# G32R502 register map
Vendor: Geehy Semiconductor Co., Ltd.; Series: G32R5; File version: 1.0
CPU: CM52 r0p1, little endian, MPU, FPU, DSP, VTOR, 4 interrupt priority bits
Registers are 32-bit, read-write, reset 0x0 unless marked. A register's access mark holds for its fields unless they carry their own. Offsets are from the block's base; [hi:lo] are bit positions; {n}, {i} and the like mark numbered series.

## DCCOMP0 — Dual-Clock Comparator
Base 0x40000000
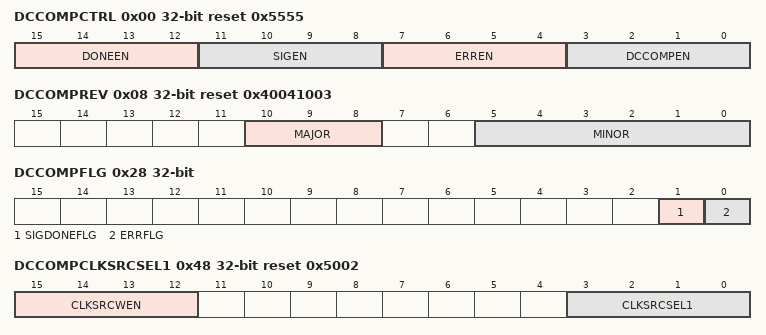
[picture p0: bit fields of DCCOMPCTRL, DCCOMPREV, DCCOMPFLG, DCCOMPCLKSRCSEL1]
0x00 DCCOMPCTRL reset 0x5555 — Global Control Register
  [15:12] DONEEN — DONE Enable
  [11:8] SIGEN — Single Shot Mode Enable
  [7:4] ERREN — Error Enable
  [3:0] DCCOMPEN — DCCOMP Enable
0x08 DCCOMPREV ro reset 0x40041003 — DCCOMP Revision Register
  [10:8] MAJOR — Minor Revision Number
  [5:0] MINOR — Major Revision Number
0x10 DCCOMPCNTSEED0 — Counter 0 Seed Value
  [19:0] CNTSEED0
0x18 DCCOMPVALSEED0 — Valid 0 Seed Value
  [15:0] VALSEED0 — Valid Duration Counter 0 Seed Value
0x20 DCCOMPCNTSEED1 — Counter 1 Seed Value
  [19:0] CNTSEED1
0x28 DCCOMPFLG — DCCOMP Status
  [1] SIGDONEFLG — Single-Shot Done Flag
  [0] ERRFLG — Error Flag
0x30 DCCOMPCLKSRCCNT0 ro — Counter 0 Value
  [19:0] CLKSRCCNT0 — Clock Source 0 counter attached Value
0x38 DCCOMPCLKSRCVAL0 ro — Valid Value 0
  [15:0] CLKSRCVAL0 — Clock Source 0 valid counter attached Value
0x40 DCCOMPCLKSRCCNT1 ro — Counter 1 Value
  [19:0] CLKSRCCNT1 — Clock Source 1 counter attached Value
0x48 DCCOMPCLKSRCSEL1 reset 0x5002 — Clock Source 1
  [15:12] CLKSRCWEN — Counter 1 Clock Source Write Enable
  [3:0] CLKSRCSEL1 — Counter 1 Clock Source Select
0x50 DCCOMPCLKSRCSEL0 reset 0x1 — Clock Source 0
  [3:0] CLKSRCSEL0 — Counter 0 Clock Source Select

## NMI — Non-maskable interrupt
Base 0x400100C0
0x00 NMICFG 16-bit — NMI Configuration Register
  [0] NMIE — Global NMI Enable
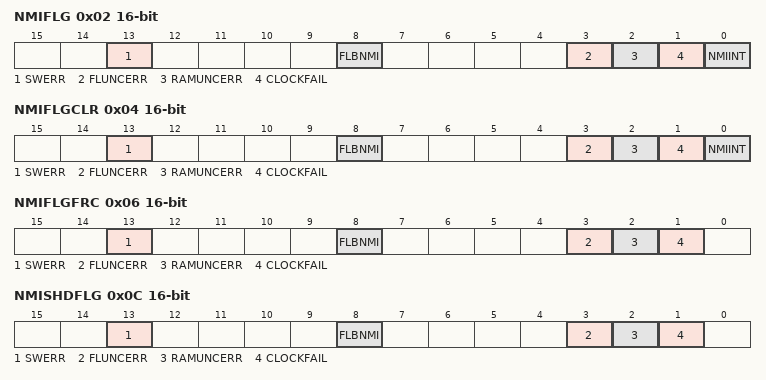
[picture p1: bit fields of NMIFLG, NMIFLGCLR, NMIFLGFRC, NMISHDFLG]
0x02 NMIFLG 16-bit ro — NMI Flag Register (SYSRsn Clear)
  [13] SWERR — Software-Forced NMI Flag
  [8] FLBNMI — FLB NMI Flag
  [3] FLUNCERR — Flash Uncorrectable Error NMI Flag
  [2] RAMUNCERR — RAM Uncorrectable Error NMI Flag
  [1] CLOCKFAIL — Clock Fail NMI Flag
  [0] NMIINT — Global NMI Flag
0x04 NMIFLGCLR 16-bit — NMI Flag Clear Register
  [13] SWERR — Clear the SWERR flag
  [8] FLBNMI — Clear the FLBNMI flag
  [3] FLUNCERR — Clear the FLUNCERR flag
  [2] RAMUNCERR — Clear the RAMUNCERR flag
  [1] CLOCKFAIL — Clear the CLOCKFAIL flag
  [0] NMIINT — Clear the NMIINT flag
0x06 NMIFLGFRC 16-bit — NMI Flag Force Register
  [13] SWERR — Set the SWERR flag
  [8] FLBNMI — Set the FLBNMI flag
  [3] FLUNCERR — Set the FLUNCERR flag
  [2] RAMUNCERR — Set the RAMUNCERR flag
  [1] CLOCKFAIL — Set the CLOCKFAIL flag
0x08 NMIWDCNT 16-bit ro — NMI Watchdog Counter Register
  [15:0] NMIWDCNT — NMI Watchdog Counter
0x0A NMIWDPRD 16-bit reset 0xFFFF — NMI Watchdog Period Register
  [15:0] NMIWDPRD — NMI Watchdog Period
0x0C NMISHDFLG 16-bit ro — NMI Shadow Flag Register
  [13] SWERR — Shadow SWERR flag
  [8] FLBNMI — Shadow FLBNMI flag
  [3] FLUNCERR — Shadow FLUNCERR flag
  [2] RAMUNCERR — Shadow RAMUNCERR flag
  [1] CLOCKFAIL — Shadow CLOCKFAIL flag
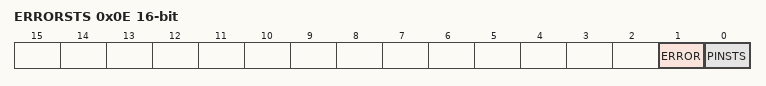
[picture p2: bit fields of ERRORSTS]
0x0E ERRORSTS 16-bit ro — Error Pin Status Register
  [1] ERROR — Error status (sticky)
  [0] PINSTS — Error pin level status
0x10 ERRORSTSCLR 16-bit — Error Pin Status Clear Register
  [0] ERROR — Clear ERRORSTS.ERROR
0x12 ERRORSTSFRC 16-bit — Error Pin Status Force Register
  [0] ERROR — Force ERRORSTS.ERROR
0x14 ERRORSTSCTL 16-bit — Error Pin Status Control Register
  [0] ERRORPOLSEL — Error pin polarity select
0x16 ERRORLOCK 16-bit — Error Pin Control Lock Register
  [0] ERRORCTL — Lock ERRORSTSCTL (write-1-set, clear by reset)

## DBGMCU
Base 0xE0059000
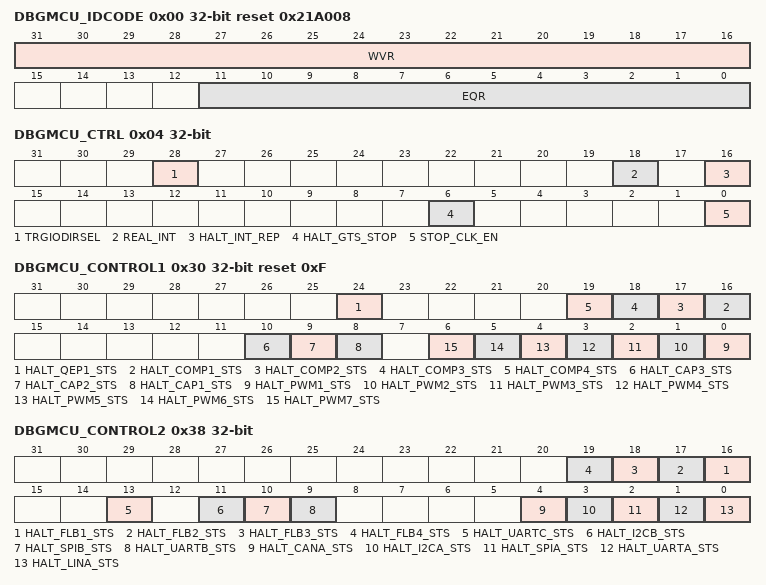
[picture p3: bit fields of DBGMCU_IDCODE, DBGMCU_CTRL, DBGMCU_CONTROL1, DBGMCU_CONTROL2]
0x00 DBGMCU_IDCODE reset 0x21A008 — Device ID register
  [31:16] WVR — Wafer Version Recognition
  [11:0] EQR — Equipment Recognition
0x04 DBGMCU_CTRL — Debug MCU Control register
  [28] TRGIODIRSEL — TRGIO direction select
  [18] REAL_INT — Interrupt run cannot enter HALT when CPU in real-time mode
  [16] HALT_INT_REP — The response is interrupt when CPU in HALT mode
  [6] HALT_GTS_STOP — The global timestamp is stop when CPU enters HALT mode
  [0] STOP_CLK_EN — Enable the system clock when MCU is debugged in stop mode
0x30 DBGMCU_CONTROL1 reset 0xF — CPU Debug MCU configuration register 1
  [24] HALT_QEP1_STS — Configure QEP1 work status when CPU is in HALT mode
  [n+15] HALT_COMP{n}_STS (n=1..4) — Configure COMP{n} work status when CPU is in HALT mode
  [10] HALT_CAP3_STS — Configure CAP3 work status when CPU is in HALT mode
  [9] HALT_CAP2_STS — Configure CAP2 work status when CPU is in HALT mode
  [8] HALT_CAP1_STS — Configure CAP1 work status when CPU is in HALT mode
  [n-1] HALT_PWM{n}_STS (n=1..7) — Configure PWM{n} work status when CPU is in HALT mode
0x38 DBGMCU_CONTROL2 — CPU Debug MCU configuration register 2
  [n+15] HALT_FLB{n}_STS (n=1..4) — Configure FLB{n} work status when CPU is in HALT mode
  [13] HALT_UARTC_STS — Configure UARTC work status when CPU is in HALT mode
  [11] HALT_I2CB_STS — Configure I2CB work status when CPU is in HALT mode
  [10] HALT_SPIB_STS — Configure SPIAB work status when CPU is in HALT mode
  [9] HALT_UARTB_STS — Configure UARTB work status when CPU is in HALT mode
  [4] HALT_CANA_STS — Configure CANA work status when CPU is in HALT mode
  [3] HALT_I2CA_STS — Configure I2CA work status when CPU is in HALT mode
  [2] HALT_SPIA_STS — Configure SPIA work status when CPU is in HALT mode
  [1] HALT_UARTA_STS — Configure UARTA work status when CPU is in HALT mode
  [0] HALT_LINA_STS — Configure LINA work status when CPU is in HALT mode
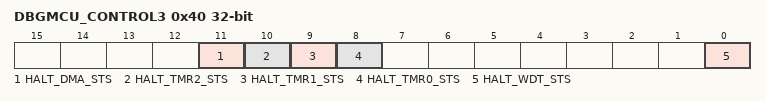
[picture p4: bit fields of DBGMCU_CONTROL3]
0x40 DBGMCU_CONTROL3 — CPU Debug MCU configuration register 3
  [11] HALT_DMA_STS — Configure DMA work status when CPU is in HALT mode
  [10] HALT_TMR2_STS — Configure TMR2 work status when CPU is in HALT mode
  [9] HALT_TMR1_STS — Configure TMR1 work status when CPU is in HALT mode
  [8] HALT_TMR0_STS — Configure TMR0 work status when CPU is in HALT mode
  [0] HALT_WDT_STS — Configure WDT work status when CPU is in HALT mode

## DWT
Base 0xE0001000
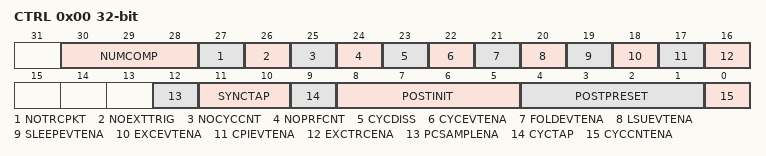
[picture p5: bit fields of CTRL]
0x00 CTRL — Control Register
  [30:28] NUMCOMP, [27] NOTRCPKT, [26] NOEXTTRIG, [25] NOCYCCNT, [24] NOPRFCNT, [23] CYCDISS, [22] CYCEVTENA, [21] FOLDEVTENA, [20] LSUEVTENA, [19] SLEEPEVTENA, [18] EXCEVTENA, [17] CPIEVTENA, [16] EXCTRCENA, [12] PCSAMPLENA, [11:10] SYNCTAP, [9] CYCTAP, [8:5] POSTINIT, [4:1] POSTPRESET, [0] CYCCNTENA
0x04 CYCCNT — Cycle Count Register
0x08 CPICNT — CPI Count Register
  [7:0] CPICNT
0x0C EXCCNT — Exception Overhead Count Register
  [7:0] EXCCNT
0x10 SLEEPCNT — Sleep Count Register
  [7:0] SLEEPCNT
0x14 LSUCNT — LSU Count Register
  [7:0] LSUCNT
0x18 FOLDCNT — Folded-instruction Count Register
  [7:0] FOLDCNT
0x1C PCSR — Program Counter Sample Register
{0x20+0x10*i} COMP{i} (i=0..7) — Comparator Register {i}
{0x28+0x10*i} FUNCTION{i} (i=0..7) — Function Register {i}
0x3C VMASK1 — Comparator Value Mask 1
0x5C VMASK3 — Comparator Value Mask 3
0xFBC DEVARCH ro — Device Type Architecture Register
0xFCC DEVTYPE ro — Device Type Identifier Register
